# STM32L4S9xx register map
File version: 1.0
Registers are 32-bit, read-write, reset 0x0 unless marked. A register's access mark holds for its fields unless they carry their own. Offsets are from the block's base; [hi:lo] are bit positions; {n}, {i} and the like mark numbered series; 'fields as' and 'values as' point back to an identical list.

## RCC — Reset and Clock Control
Base 0x40021000
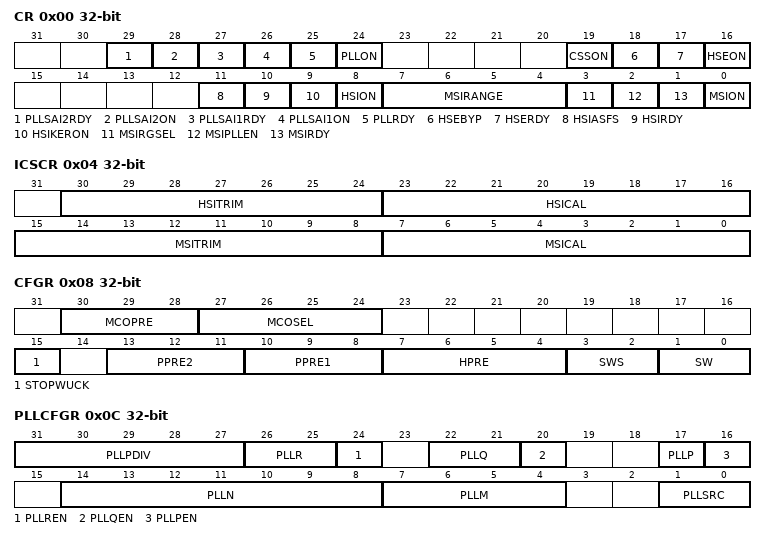
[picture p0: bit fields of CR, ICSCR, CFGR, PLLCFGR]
0x00 CR — RCC clock control register
  [29] PLLSAI2RDY — SAI2 PLL ready
  [28] PLLSAI2ON — SAI2 PLL enable
  [27] PLLSAI1RDY — SAI1 PLL ready
  [26] PLLSAI1ON — SAI1 PLL enable
  [25] PLLRDY — System PLL clock ready
  [24] PLLON — System PLL clock enable
  [19] CSSON — HSE Clock Security System enable
  [18] HSEBYP — External High Speed oscillator (HSE) clock bypass
  [17] HSERDY — External High Speed oscillator (HSE) clock ready
  [16] HSEON — External High Speed oscillator (HSE) clock enable
  [11] HSIASFS — HSI16 Automatic Start from Stop
  [10] HSIRDY — Internal High Speed oscillator (HSI16) clock ready flag
  [9] HSIKERON — Internal High Speed oscillator (HSI16) clock enable for some IPs Kernel
  [8] HSION — Internal High Speed oscillator (HSI16) clock enable
  [7:4] MSIRANGE — Internal Multi Speed oscillator (MSI) clock Range
    0=MSI = 100 KHz; 1=MSI = 200 KHz; 2=MSI = 400 KHz; 3=MSI = 800 KHz; 4=MSI = 1 MHz; 5=MSI = 2 MHz; 6=MSI = 4 MHz; 7=MSI = 8 MHz; 8=MSI = 16 MHz; 9=MSI = 24 MHz; 10=MSI = 32 MHz; 11=MSI = 48 MHz
  [3] MSIRGSEL — Internal Multi Speed oscillator (MSI) range selection
  [2] MSIPLLEN — Internal Multi Speed oscillator (MSI) PLL enable
  [1] MSIRDY — Internal Multi Speed oscillator (MSI) clock ready flag
  [0] MSION — Internal Multi Speed oscillator (MSI) clock enable
0x04 ICSCR — RCC internal clock sources calibration register
  [30:24] HSITRIM — HSITRIM[6:0] bits
  [23:16] HSICAL — HSICAL[7:0] bits
  [15:8] MSITRIM — MSITRIM[7:0] bits
  [7:0] MSICAL — MSICAL[7:0] bits
0x08 CFGR — RCC clock configuration register
  [30:28] MCOPRE — MCO prescaler
  [27:24] MCOSEL — MCOSEL [3:0] bits (Clock output selection)
  [15] STOPWUCK — Wake Up from stop and CSS backup clock selection
    0=MSI (MSI selection after wake-up from STOP); 1=HSI (HSI selection after wake-up from STOP)
  [13:11] PPRE2 — PRE2[2:0] bits (APB2 prescaler)
    0=DIV_1 (HCLK not divided); 4=DIV_2 (HCLK divided by 2); 5=DIV_4 (HCLK divided by 4); 6=DIV_8 (HCLK divided by 8); 7=DIV_16 (HCLK divided by 16)
  [10:8] PPRE1 — PRE1[2:0] bits (APB2 prescaler)
    values as PPRE2
  [7:4] HPRE — HPRE[3:0] bits (AHB prescaler)
    0=DIV_1 (SYSCLK not divided); 8=DIV_2 (SYSCLK divided by 2); 9=DIV_4 (SYSCLK divided by 4); 10=DIV_8 (SYSCLK divided by 8); 11=DIV_16 (SYSCLK divided by 16); 12=DIV_64 (SYSCLK divided by 64); 13=DIV_128 (SYSCLK divided by 128); 14=DIV_256 (SYSCLK divided by 256); 15=DIV_512 (SYSCLK divided by 512)
  [3:2] SWS — SWS[1:0] bits (System Clock Switch Status)
    0=MSI (MSI used as system clock); 1=HSI (HSI used as system clock); 2=HSE (HSE used as system clock); 3=PLL (PLL used as system clock)
  [1:0] SW — SW[1:0] bits (System clock Switch)
    0=MSI (MSI selection as system clock); 1=HSI (HSI selection as system clock); 2=HSE (HSE selection as system clock); 3=PLL (PLL selection as system clock)
0x0C PLLCFGR — RCC system PLL configuration register
  [31:27] PLLPDIV
    {v}=DIV_{v} (Main PLL division factor for PLLP output by {v}) (v=2..31)
  [26:25] PLLR
    0=DIV_2 (Main PLL division factor for PLLCLK (system clock) by 2); 1=DIV_4 (Main PLL division factor for PLLCLK (system clock) by 4); 2=DIV_6 (Main PLL division factor for PLLCLK (system clock) by 6); 3=DIV_8 (Main PLL division factor for PLLCLK (system clock) by 8)
  [24] PLLREN
  [22:21] PLLQ
    0=DIV_2 (Main PLL division factor for PLLQ output by 2); 1=DIV_4 (Main PLL division factor for PLLQ output by 4); 2=DIV_6 (Main PLL division factor for PLLQ output by 6); 3=DIV_8 (Main PLL division factor for PLLQ output by 8)
  [20] PLLQEN
  [17] PLLP
  [16] PLLPEN
  [14:8] PLLN
  [7:4] PLLM
    {v}=DIV_{v+1} (Main PLL division factor for PLLM input by {v+1}) (v=0..15)
  [1:0] PLLSRC
    0=NONE (No clock); 1=MSI (MSI clock selected as PLL entry clock source); 2=HSI (HSI16 clock selected as PLL entry clock source); 3=HSE (HSE clock selected as PLL entry clock source)
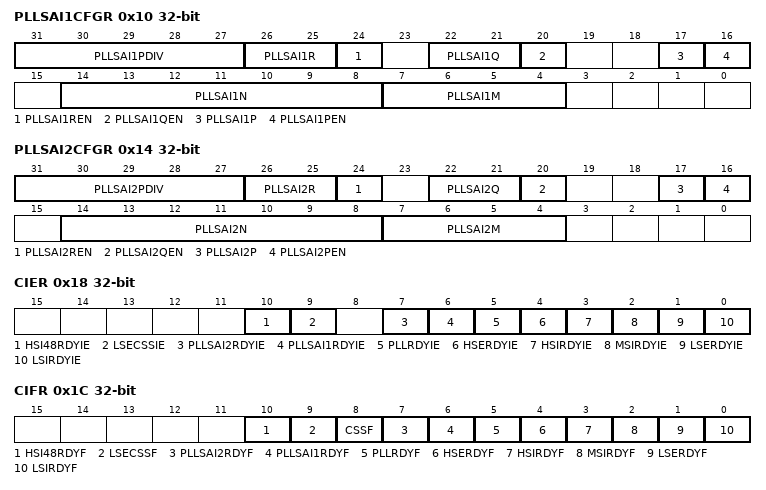
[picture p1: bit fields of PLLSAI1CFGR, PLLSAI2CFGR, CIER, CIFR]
0x10 PLLSAI1CFGR — RCC PLL SAI1 configuration register
  [31:27] PLLSAI1PDIV
    {v}=DIV_{v} (PLLSAI1 division factor for PLLSAI1P output by {v}) (v=2..10); 11=DIV_11 (PLLSAI1 division factor for PLLSAI1P output by 1); {v}=DIV_{v} (PLLSAI1 division factor for PLLSAI1P output by {v}) (v=12..20); 21=DIV_21 (PLLSAI1 division fctor for PLLSAI1P output by 21); {v}=DIV_{v} (PLLSAI1 division factor for PLLSAI1P output by {v}) (v=22..31)
  [26:25] PLLSAI1R
    0=DIV_2 (PLLSAI1 division factor for PLLSAI1R output by 2); 1=DIV_4 (PLLSAI1 division factor for PLLSAI1R output by 4); 2=DIV_6 (PLLSAI1 division factor for PLLSAI1R output by 6); 3=DIV_8 (PLLSAI1 division factor for PLLSAI1R output by 8)
  [24] PLLSAI1REN
  [22:21] PLLSAI1Q
    0=DIV_2 (PLLSAI1 division factor for PLLSAI1Q output by 2); 1=DIV_4 (PLLSAI1 division factor for PLLSAI1Q output by 4); 2=DIV_6 (PLLSAI1 division factor for PLLSAI1Q output by 6); 3=DIV_8 (PLLSAI1 division factor for PLLSAI1Q output by 8)
  [20] PLLSAI1QEN
  [17] PLLSAI1P
  [16] PLLSAI1PEN
  [14:8] PLLSAI1N
  [7:4] PLLSAI1M
    {v}=DIV_{v+1} (PLLSAI1 division factor for PLLSAI1M input by {v+1}) (v=0..15)
0x14 PLLSAI2CFGR — RCC PLL SAI2 configuration register
  [31:27] PLLSAI2PDIV
    {v}=DIV_{v} (PLLSAI2 division factor for PLLSAI2P output by {v}) (v=2..10); 11=DIV_11 (PLLSAI2 division factor for PLLSAI2P output by 1); {v}=DIV_{v} (PLLSAI2 division factor for PLLSAI2P output by {v}) (v=12..20); 21=DIV_21 (PLLSAI2 division fctor for PLLSAI2P output by 21); {v}=DIV_{v} (PLLSAI2 division factor for PLLSAI2P output by {v}) (v=22..30); 31=DIV_31 (PLLSAI1 division factor for PLLSAI1P output by 31)
  [26:25] PLLSAI2R
    0=DIV_2 (PLLSAI2 division factor for PLLSAI2R output by 2); 1=DIV_4 (PLLSAI2 division factor for PLLSAI2R output by 4); 2=DIV_6 (PLLSAI2 division factor for PLLSAI2R output by 6); 3=DIV_8 (PLLSAI2 division factor for PLLSAI2R output by 8)
  [24] PLLSAI2REN
  [22:21] PLLSAI2Q
    0=DIV_2 (PLLSAI2 division factor for PLLSAI2Q output by 2); 1=DIV_4 (PLLSAI2 division factor for PLLSAI2Q output by 4); 2=DIV_6 (PLLSAI2 division factor for PLLSAI2Q output by 6); 3=DIV_8 (PLLSAI2 division factor for PLLSAI2Q output by 8)
  [20] PLLSAI2QEN
  [17] PLLSAI2P
  [16] PLLSAI2PEN
  [14:8] PLLSAI2N
  [7:4] PLLSAI2M
    {v}=DIV_{v+1} (PLLSAI2 division factor for PLLSAI2M input by {v+1}) (v=0..15)
0x18 CIER — RCC clock interrupt enable register
  [10] HSI48RDYIE, [9] LSECSSIE, [7] PLLSAI2RDYIE, [6] PLLSAI1RDYIE, [5] PLLRDYIE, [4] HSERDYIE, [3] HSIRDYIE, [2] MSIRDYIE, [1] LSERDYIE, [0] LSIRDYIE
0x1C CIFR — RCC clock interrupt flag register
  [10] HSI48RDYF, [9] LSECSSF, [8] CSSF, [7] PLLSAI2RDYF, [6] PLLSAI1RDYF, [5] PLLRDYF, [4] HSERDYF, [3] HSIRDYF, [2] MSIRDYF, [1] LSERDYF, [0] LSIRDYF
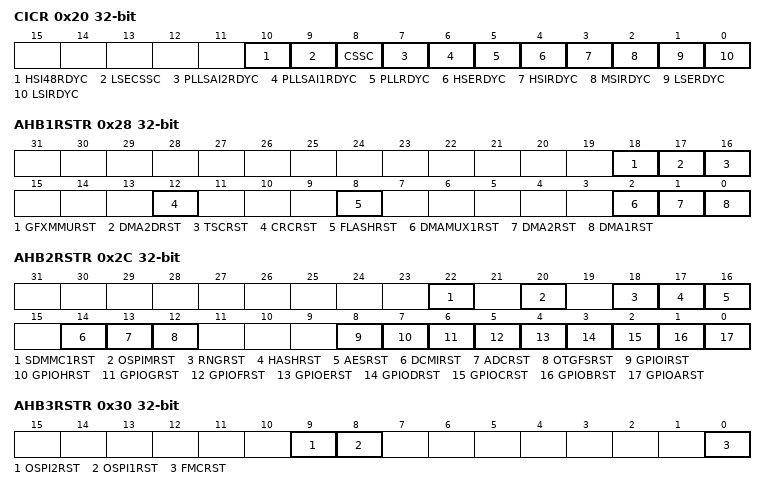
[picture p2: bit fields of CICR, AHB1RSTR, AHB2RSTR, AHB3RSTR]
0x20 CICR — RCC clock interrupt clear register
  [10] HSI48RDYC, [9] LSECSSC, [8] CSSC, [7] PLLSAI2RDYC, [6] PLLSAI1RDYC, [5] PLLRDYC, [4] HSERDYC, [3] HSIRDYC, [2] MSIRDYC, [1] LSERDYC, [0] LSIRDYC
0x28 AHB1RSTR — RCC AHB1 peripheral reset register
  [18] GFXMMURST, [17] DMA2DRST, [16] TSCRST, [12] CRCRST, [8] FLASHRST, [2] DMAMUX1RST, [1] DMA2RST, [0] DMA1RST
0x2C AHB2RSTR — RCC AHB2 peripheral reset register
  [22] SDMMC1RST, [20] OSPIMRST, [18] RNGRST, [17] HASHRST, [16] AESRST, [14] DCMIRST, [13] ADCRST, [12] OTGFSRST, [8] GPIOIRST, [7] GPIOHRST, [6] GPIOGRST, [5] GPIOFRST, [4] GPIOERST, [3] GPIODRST, [2] GPIOCRST, [1] GPIOBRST, [0] GPIOARST
0x30 AHB3RSTR — RCC AHB3 peripheral reset register
  [9] OSPI2RST, [8] OSPI1RST, [0] FMCRST
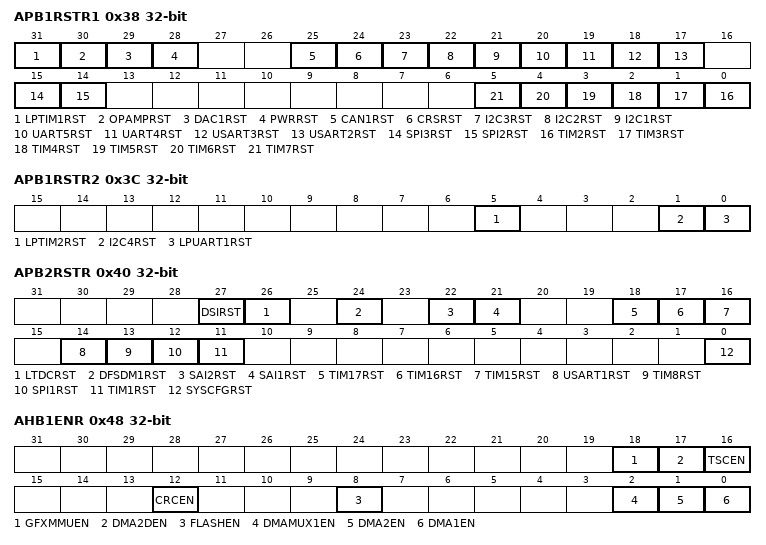
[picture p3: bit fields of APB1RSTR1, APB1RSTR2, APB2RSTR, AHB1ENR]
0x38 APB1RSTR1 — RCC APB1 peripheral reset register 1
  [31] LPTIM1RST, [30] OPAMPRST, [29] DAC1RST, [28] PWRRST, [25] CAN1RST, [24] CRSRST, [23] I2C3RST, [22] I2C2RST, [21] I2C1RST, [20] UART5RST, [19] UART4RST, [18] USART3RST, [17] USART2RST, [15] SPI3RST, [14] SPI2RST, [n-2] TIM{n}RST (n=2..7)
0x3C APB1RSTR2 — RCC APB1 peripheral reset register 2
  [5] LPTIM2RST, [1] I2C4RST, [0] LPUART1RST
0x40 APB2RSTR — RCC APB2 peripheral reset register
  [27] DSIRST, [26] LTDCRST, [24] DFSDM1RST, [22] SAI2RST, [21] SAI1RST, [18] TIM17RST, [17] TIM16RST, [16] TIM15RST, [14] USART1RST, [13] TIM8RST, [12] SPI1RST, [11] TIM1RST, [0] SYSCFGRST
0x48 AHB1ENR — RCC AHB1 peripheral clocks enable register
  [18] GFXMMUEN, [17] DMA2DEN, [16] TSCEN, [12] CRCEN, [8] FLASHEN, [2] DMAMUX1EN, [1] DMA2EN, [0] DMA1EN
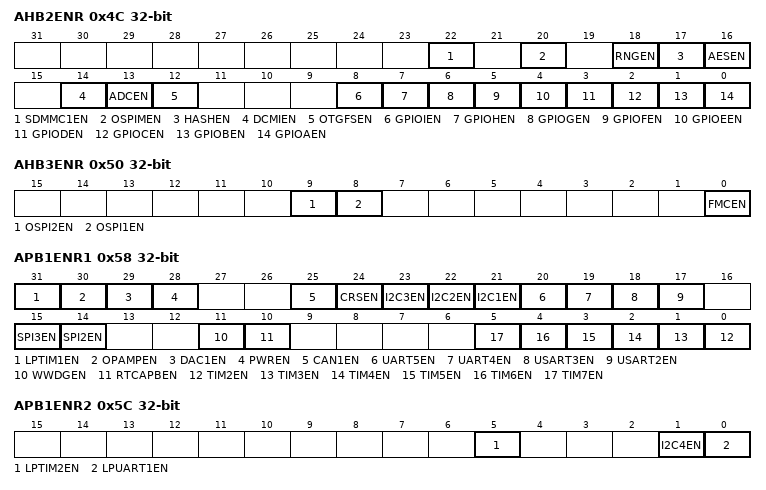
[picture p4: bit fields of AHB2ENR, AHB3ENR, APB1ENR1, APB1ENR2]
0x4C AHB2ENR — RCC AHB2 peripheral clocks enable register
  [22] SDMMC1EN, [20] OSPIMEN, [18] RNGEN, [17] HASHEN, [16] AESEN, [14] DCMIEN, [13] ADCEN, [12] OTGFSEN, [8] GPIOIEN, [7] GPIOHEN, [6] GPIOGEN, [5] GPIOFEN, [4] GPIOEEN, [3] GPIODEN, [2] GPIOCEN, [1] GPIOBEN, [0] GPIOAEN
0x50 AHB3ENR — RCC AHB3 peripheral clocks enable register
  [9] OSPI2EN, [8] OSPI1EN, [0] FMCEN
0x58 APB1ENR1 — RCC APB1 peripheral clocks enable register 1
  [31] LPTIM1EN, [30] OPAMPEN, [29] DAC1EN, [28] PWREN, [25] CAN1EN, [24] CRSEN, [23] I2C3EN, [22] I2C2EN, [21] I2C1EN, [20] UART5EN, [19] UART4EN, [18] USART3EN, [17] USART2EN, [15] SPI3EN, [14] SPI2EN, [11] WWDGEN, [10] RTCAPBEN, [n-2] TIM{n}EN (n=2..7)
0x5C APB1ENR2 — RCC APB1 peripheral clocks enable register 2
  [5] LPTIM2EN, [1] I2C4EN, [0] LPUART1EN
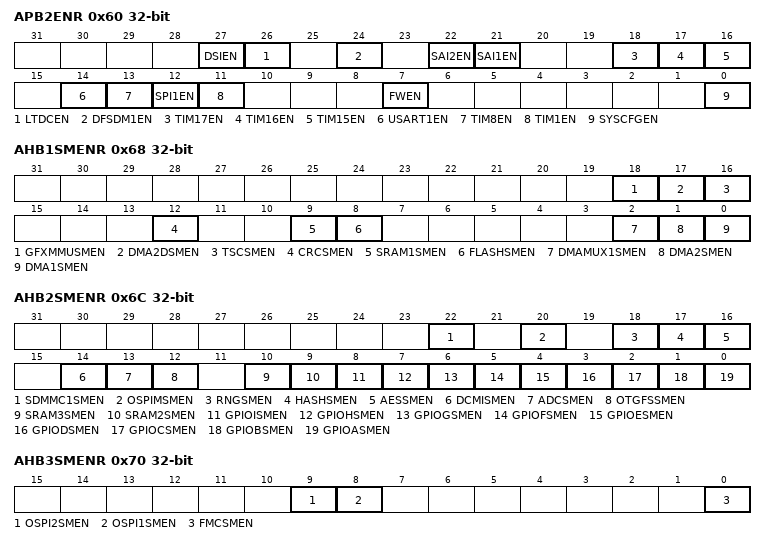
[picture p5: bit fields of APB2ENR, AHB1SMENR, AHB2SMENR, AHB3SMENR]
0x60 APB2ENR — RCC APB2 peripheral clocks enable register
  [27] DSIEN, [26] LTDCEN, [24] DFSDM1EN, [22] SAI2EN, [21] SAI1EN, [18] TIM17EN, [17] TIM16EN, [16] TIM15EN, [14] USART1EN, [13] TIM8EN, [12] SPI1EN, [11] TIM1EN, [7] FWEN, [0] SYSCFGEN
0x68 AHB1SMENR — RCC AHB1 peripheral clocks enable in sleep and stop modes register
  [18] GFXMMUSMEN, [17] DMA2DSMEN, [16] TSCSMEN, [12] CRCSMEN, [9] SRAM1SMEN, [8] FLASHSMEN, [2] DMAMUX1SMEN, [1] DMA2SMEN, [0] DMA1SMEN
0x6C AHB2SMENR — RCC AHB2 peripheral clocks enable in sleep and stop modes register
  [22] SDMMC1SMEN, [20] OSPIMSMEN, [18] RNGSMEN, [17] HASHSMEN, [16] AESSMEN, [14] DCMISMEN, [13] ADCSMEN, [12] OTGFSSMEN, [10] SRAM3SMEN, [9] SRAM2SMEN, [8] GPIOISMEN, [7] GPIOHSMEN, [6] GPIOGSMEN, [5] GPIOFSMEN, [4] GPIOESMEN, [3] GPIODSMEN, [2] GPIOCSMEN, [1] GPIOBSMEN, [0] GPIOASMEN
0x70 AHB3SMENR — RCC AHB3 peripheral clocks enable in sleep and stop modes register
  [9] OSPI2SMEN, [8] OSPI1SMEN, [0] FMCSMEN
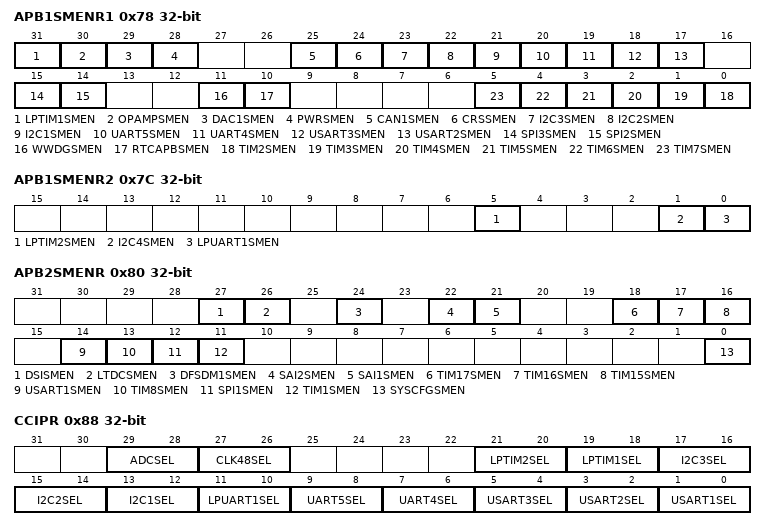
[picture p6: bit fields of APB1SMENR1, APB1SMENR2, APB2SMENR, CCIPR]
0x78 APB1SMENR1 — RCC APB1 peripheral clocks enable in sleep mode and stop modes register 1
  [31] LPTIM1SMEN, [30] OPAMPSMEN, [29] DAC1SMEN, [28] PWRSMEN, [25] CAN1SMEN, [24] CRSSMEN, [23] I2C3SMEN, [22] I2C2SMEN, [21] I2C1SMEN, [20] UART5SMEN, [19] UART4SMEN, [18] USART3SMEN, [17] USART2SMEN, [15] SPI3SMEN, [14] SPI2SMEN, [11] WWDGSMEN, [10] RTCAPBSMEN, [n-2] TIM{n}SMEN (n=2..7)
0x7C APB1SMENR2 — RCC APB1 peripheral clocks enable in sleep mode and stop modes register 2
  [5] LPTIM2SMEN, [1] I2C4SMEN, [0] LPUART1SMEN
0x80 APB2SMENR — RCC APB2 peripheral clocks enable in sleep mode and stop modes register
  [27] DSISMEN, [26] LTDCSMEN, [24] DFSDM1SMEN, [22] SAI2SMEN, [21] SAI1SMEN, [18] TIM17SMEN, [17] TIM16SMEN, [16] TIM15SMEN, [14] USART1SMEN, [13] TIM8SMEN, [12] SPI1SMEN, [11] TIM1SMEN, [0] SYSCFGSMEN
0x88 CCIPR — RCC peripherals independent clock configuration register
  [29:28] ADCSEL
    0=NONE (No clock used as ADC clock source); 1=PLLSAI1 (PLLSAI1 clock used as ADC clock source); 3=SYSCLK (SYSCLK clock used as ADC clock source)
  [27:26] CLK48SEL
    0=HSI48 (HSI48 clock used as SDMMC1 clock source); 1=PLLSAI1 (PLLSAI1 clock used as SDMMC1 clock source); 2=PLL (PLL clock used as SDMMC1 clock source); 3=MSI (MSI clock used as SDMMC1 clock source)
  [21:20] LPTIM2SEL
  [19:18] LPTIM1SEL
  [17:16] I2C3SEL
  [15:14] I2C2SEL
  [13:12] I2C1SEL
  [11:10] LPUART1SEL
    0=PCLK1 (PCLK1 clock used as LPUART1 clock source); 1=SYSCLK (SYSCLK clock used as LPUART1 clock source); 2=HSI (HSI clock used as LPUART1 clock source); 3=LSE (LSE clock used as LPUART1 clock source)
  [9:8] UART5SEL
  [7:6] UART4SEL
  [5:4] USART3SEL
  [3:2] USART2SEL
  [1:0] USART1SEL
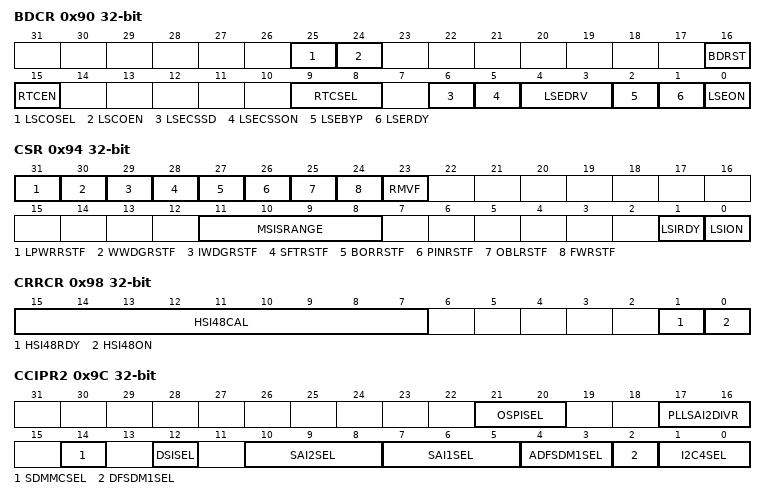
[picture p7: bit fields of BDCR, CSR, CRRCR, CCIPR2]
0x90 BDCR — RCC backup domain control register
  [25] LSCOSEL
    0=LSI (LSI selection for low speed clock); 1=LSE (LSE selection for low speed clock)
  [24] LSCOEN
  [16] BDRST
  [15] RTCEN
  [9:8] RTCSEL
    0=NONE (No clock used as RTC clock); 1=LSE (LSE oscillator clock used as RTC clock); 2=LSI (LSI oscillator clock used as RTC clock); 3=HSE_DIV32 (HSE oscillator clock divided by 32 used as RTC clock)
  [6] LSECSSD
  [5] LSECSSON
  [4:3] LSEDRV
    0=LOW (Xtal mode lower driving capability); 1=MEDIUMLOW (Xtal mode medium low driving capability); 2=MEDIUMHIGH (Xtal mode medium high driving capability); 3=HIGH (Xtal mode higher driving capability)
  [2] LSEBYP
  [1] LSERDY
  [0] LSEON
0x94 CSR — RCC clock control & status register
  [31] LPWRRSTF
  [30] WWDGRSTF
  [29] IWDGRSTF
  [28] SFTRSTF
  [27] BORRSTF
  [26] PINRSTF
  [25] OBLRSTF
  [24] FWRSTF
  [23] RMVF
  [11:8] MSISRANGE
    4=MSI = 1 MHz; 5=MSI = 2 MHz; 6=MSI = 4 MHz; 7=MSI = 8 MHz
  [1] LSIRDY
  [0] LSION
0x98 CRRCR — RCC clock recovery RC register
  [15:7] HSI48CAL — HSI48CAL[8:0] bits
  [1] HSI48RDY
  [0] HSI48ON
0x9C CCIPR2 — RCC peripherals independent clock configuration register 2
  [21:20] OSPISEL
    0=SYSCLK (SYSCLK used as OctoSPI clock source); 1=MSI (MSI used as OctoSPI clock source); 2=PLL (PLL used as OctoSPI clock source)
  [17:16] PLLSAI2DIVR
    0=DIV2 (PLLSAI2DIVR divided by 2 used as LTDC clock source); 1=DIV4 (PLLSAI2DIVR divided by 4 used as LTDC clock source); 2=DIV8 (PLLSAI2DIVR divided by 8 used as LTDC clock source); 3=DIV16 (PLLSAI2DIVR divided by 16 used as LTDC clock source)
  [14] SDMMCSEL
    0=KERNELCLKSOURCE_48CLK (48MHz clock from internal multiplexor used as SDMMC1 clock source); 1=PLLP (PLLSAI3CLK clock used as SDMMC1 clock source)
  [12] DSISEL
    0=PHY (DSI-PHY clock used as DSI byte lane clock source); 1=PLL (PLL clock used as DSI byte lane clock source)
  [10:8] SAI2SEL
  [7:5] SAI1SEL
  [4:3] ADFSDM1SEL
    0=SAI1 (SAI1 clock used as DFSDM1 Audio clock); 1=HSI (HSI clock used as DFSDM1 Audio clock); 2=MSI (MSI clock used as DFSDM1 Audio clock)
  [2] DFSDM1SEL
  [1:0] I2C4SEL
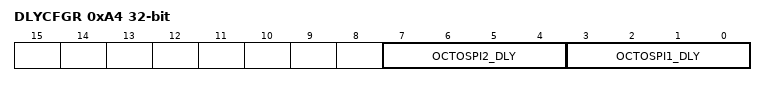
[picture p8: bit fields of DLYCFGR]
0xA4 DLYCFGR — RCC peripheral OCTOSPI delay configuration register
  [7:4] OCTOSPI2_DLY, [3:0] OCTOSPI1_DLY
